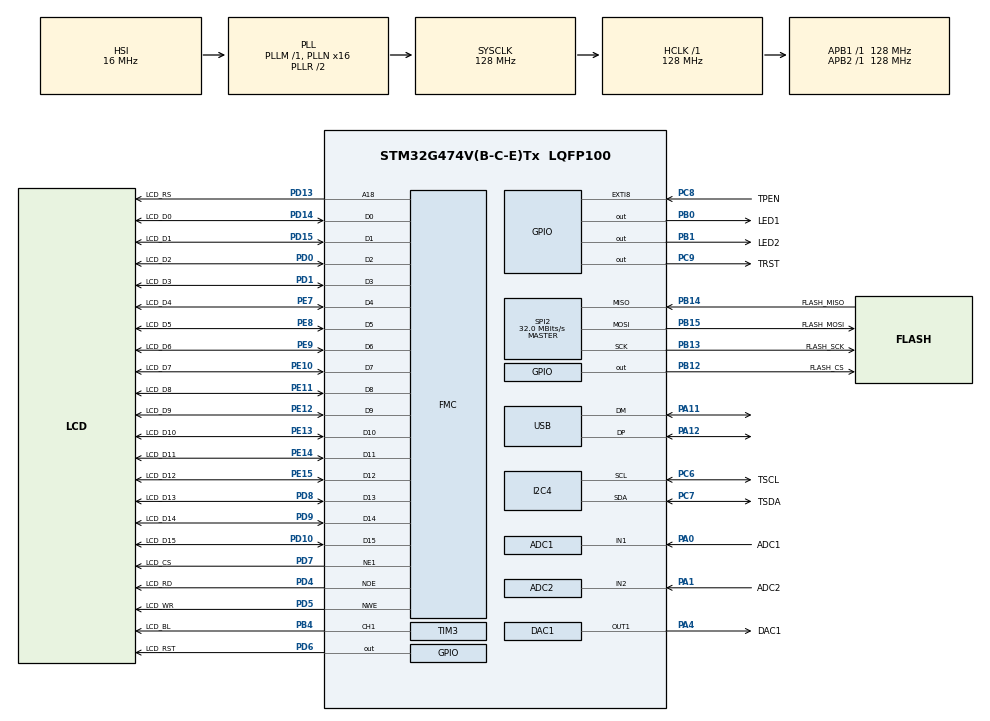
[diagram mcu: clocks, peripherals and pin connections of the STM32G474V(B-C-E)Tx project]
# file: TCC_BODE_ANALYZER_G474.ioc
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ADC1.Channel-1\#ChannelRegularConversion=ADC_CHANNEL_1
ADC1.ContinuousConvMode=DISABLE
ADC1.DMAContinuousRequests=ENABLE
ADC1.ExternalTrigConv=ADC_EXTERNALTRIG_T2_TRGO
ADC1.Mode=ADC_MODE_INDEPENDENT
ADC1.NbrOfConversionFlag=1
ADC1.OffsetNumber-1\#ChannelRegularConversion=ADC_OFFSET_NONE
ADC1.Overrun=ADC_OVR_DATA_OVERWRITTEN
ADC1.Rank-1\#ChannelRegularConversion=1
ADC1.SamplingTime-1\#ChannelRegularConversion=ADC_SAMPLETIME_2CYCLES_5
ADC1.master=1
ADC2.Channel-0\#ChannelRegularConversion=ADC_CHANNEL_2
ADC2.DMAContinuousRequests=ENABLE
ADC2.ExternalTrigConv=ADC_EXTERNALTRIG_T2_TRGO
ADC2.NbrOfConversionFlag=1
ADC2.OffsetNumber-0\#ChannelRegularConversion=ADC_OFFSET_NONE
ADC2.Rank-0\#ChannelRegularConversion=1
ADC2.SamplingTime-0\#ChannelRegularConversion=ADC_SAMPLETIME_2CYCLES_5
DAC1.DAC_OutputBuffer-DAC_OUT1=DAC_OUTPUTBUFFER_DISABLE
DAC1.DAC_Trigger_OUT1-DAC_OUT1=DAC_TRIGGER_T2_TRGO
Dma.ADC1.4.Direction=DMA_PERIPH_TO_MEMORY
Dma.ADC1.4.EventEnable=DISABLE
Dma.ADC1.4.Instance=DMA1_Channel5
Dma.ADC1.4.MemDataAlignment=DMA_MDATAALIGN_HALFWORD
Dma.ADC1.4.MemInc=DMA_MINC_ENABLE
Dma.ADC1.4.Mode=DMA_CIRCULAR
Dma.ADC1.4.PeriphDataAlignment=DMA_PDATAALIGN_HALFWORD
Dma.ADC1.4.PeriphInc=DMA_PINC_DISABLE
Dma.ADC1.4.Polarity=HAL_DMAMUX_REQ_GEN_RISING
Dma.ADC1.4.Priority=DMA_PRIORITY_HIGH
Dma.ADC1.4.RequestNumber=1
Dma.ADC1.4.SignalID=NONE
Dma.ADC1.4.SyncEnable=DISABLE
Dma.ADC1.4.SyncPolarity=HAL_DMAMUX_SYNC_NO_EVENT
Dma.ADC1.4.SyncRequestNumber=1
Dma.ADC1.4.SyncSignalID=NONE
Dma.ADC2.5.Direction=DMA_PERIPH_TO_MEMORY
Dma.ADC2.5.EventEnable=DISABLE
Dma.ADC2.5.Instance=DMA1_Channel6
Dma.ADC2.5.MemDataAlignment=DMA_MDATAALIGN_HALFWORD
Dma.ADC2.5.MemInc=DMA_MINC_ENABLE
Dma.ADC2.5.Mode=DMA_CIRCULAR
Dma.ADC2.5.PeriphDataAlignment=DMA_PDATAALIGN_HALFWORD
Dma.ADC2.5.PeriphInc=DMA_PINC_DISABLE
Dma.ADC2.5.Polarity=HAL_DMAMUX_REQ_GEN_RISING
Dma.ADC2.5.Priority=DMA_PRIORITY_HIGH
Dma.ADC2.5.RequestNumber=1
Dma.ADC2.5.SignalID=NONE
Dma.ADC2.5.SyncEnable=DISABLE
Dma.ADC2.5.SyncPolarity=HAL_DMAMUX_SYNC_NO_EVENT
Dma.ADC2.5.SyncRequestNumber=1
Dma.ADC2.5.SyncSignalID=NONE
Dma.DAC1_CH1.3.Direction=DMA_MEMORY_TO_PERIPH
Dma.DAC1_CH1.3.EventEnable=DISABLE
Dma.DAC1_CH1.3.Instance=DMA1_Channel4
Dma.DAC1_CH1.3.MemDataAlignment=DMA_MDATAALIGN_HALFWORD
Dma.DAC1_CH1.3.MemInc=DMA_MINC_ENABLE
Dma.DAC1_CH1.3.Mode=DMA_CIRCULAR
Dma.DAC1_CH1.3.PeriphDataAlignment=DMA_PDATAALIGN_WORD
Dma.DAC1_CH1.3.PeriphInc=DMA_PINC_DISABLE
Dma.DAC1_CH1.3.Polarity=HAL_DMAMUX_REQ_GEN_RISING
Dma.DAC1_CH1.3.Priority=DMA_PRIORITY_VERY_HIGH
Dma.DAC1_CH1.3.RequestNumber=1
Dma.DAC1_CH1.3.SignalID=NONE
Dma.DAC1_CH1.3.SyncEnable=DISABLE
Dma.DAC1_CH1.3.SyncPolarity=HAL_DMAMUX_SYNC_NO_EVENT
Dma.DAC1_CH1.3.SyncRequestNumber=1
Dma.DAC1_CH1.3.SyncSignalID=NONE
Dma.MEMTOMEM.2.Direction=DMA_MEMORY_TO_MEMORY
Dma.MEMTOMEM.2.EventEnable=DISABLE
Dma.MEMTOMEM.2.Instance=DMA1_Channel3
Dma.MEMTOMEM.2.MemDataAlignment=DMA_MDATAALIGN_HALFWORD
Dma.MEMTOMEM.2.MemInc=DMA_MINC_ENABLE
Dma.MEMTOMEM.2.Mode=DMA_NORMAL
Dma.MEMTOMEM.2.PeriphDataAlignment=DMA_PDATAALIGN_HALFWORD
Dma.MEMTOMEM.2.PeriphInc=DMA_PINC_ENABLE
Dma.MEMTOMEM.2.Polarity=HAL_DMAMUX_REQ_GEN_RISING
Dma.MEMTOMEM.2.Priority=DMA_PRIORITY_LOW
Dma.MEMTOMEM.2.RequestNumber=1
Dma.MEMTOMEM.2.SignalID=NONE
Dma.MEMTOMEM.2.SyncEnable=DISABLE
Dma.MEMTOMEM.2.SyncPolarity=HAL_DMAMUX_SYNC_NO_EVENT
Dma.MEMTOMEM.2.SyncRequestNumber=1
Dma.MEMTOMEM.2.SyncSignalID=NONE
Dma.Request0=SPI2_RX
Dma.Request1=SPI2_TX
Dma.Request2=MEMTOMEM
Dma.Request3=DAC1_CH1
Dma.Request4=ADC1
Dma.Request5=ADC2
Dma.SPI2_RX.0.Direction=DMA_PERIPH_TO_MEMORY
Dma.SPI2_RX.0.EventEnable=DISABLE
Dma.SPI2_RX.0.Instance=DMA1_Channel1
Dma.SPI2_RX.0.MemDataAlignment=DMA_MDATAALIGN_BYTE
Dma.SPI2_RX.0.MemInc=DMA_MINC_ENABLE
Dma.SPI2_RX.0.Mode=DMA_NORMAL
Dma.SPI2_RX.0.PeriphDataAlignment=DMA_PDATAALIGN_BYTE
Dma.SPI2_RX.0.PeriphInc=DMA_PINC_DISABLE
Dma.SPI2_RX.0.Polarity=HAL_DMAMUX_REQ_GEN_RISING
Dma.SPI2_RX.0.Priority=DMA_PRIORITY_LOW
Dma.SPI2_RX.0.RequestNumber=1
Dma.SPI2_RX.0.SignalID=NONE
Dma.SPI2_RX.0.SyncEnable=DISABLE
Dma.SPI2_RX.0.SyncPolarity=HAL_DMAMUX_SYNC_NO_EVENT
Dma.SPI2_RX.0.SyncRequestNumber=1
Dma.SPI2_RX.0.SyncSignalID=NONE
Dma.SPI2_TX.1.Direction=DMA_MEMORY_TO_PERIPH
Dma.SPI2_TX.1.EventEnable=DISABLE
Dma.SPI2_TX.1.Instance=DMA1_Channel2
Dma.SPI2_TX.1.MemDataAlignment=DMA_MDATAALIGN_BYTE
Dma.SPI2_TX.1.MemInc=DMA_MINC_ENABLE
Dma.SPI2_TX.1.Mode=DMA_NORMAL
Dma.SPI2_TX.1.PeriphDataAlignment=DMA_PDATAALIGN_BYTE
Dma.SPI2_TX.1.PeriphInc=DMA_PINC_DISABLE
Dma.SPI2_TX.1.Polarity=HAL_DMAMUX_REQ_GEN_RISING
Dma.SPI2_TX.1.Priority=DMA_PRIORITY_LOW
Dma.SPI2_TX.1.RequestNumber=1
Dma.SPI2_TX.1.SignalID=NONE
Dma.SPI2_TX.1.SyncEnable=DISABLE
Dma.SPI2_TX.1.SyncPolarity=HAL_DMAMUX_SYNC_NO_EVENT
Dma.SPI2_TX.1.SyncRequestNumber=1
Dma.SPI2_TX.1.SyncSignalID=NONE
FMC.AddressSetupTime1=0
FMC.DataSetupTime1=1
FMC.ExtendedAddressSetupTime1=0
FMC.ExtendedDataSetupTime1=1
FMC.ExtendedMode1=FMC_EXTENDED_MODE_ENABLE
FREERTOS.BinarySemaphores01=FlashDMASem,Dynamic,NULL;AcquisitionSem,Dynamic,NULL;DacIntSem,Dynamic,NULL
FREERTOS.Mutexes01=ExtFlashMtx,Dynamic,NULL
FREERTOS.Tasks01=AcquisitionTask,32,4096,AcquisitionTaskEntry,As weak,NULL,Dynamic,NULL,NULL;TouchGFXTask,8,4096,TouchGFX_Task,As external,NULL,Dynamic,NULL,NULL;SampleTouch,8,256,SampleTouch_Task,As external,NULL,Dynamic,NULL,NULL
FREERTOS.configTOTAL_HEAP_SIZE=51200
FREERTOS.configUSE_NEWLIB_REENTRANT=1
FREERTOS.configUSE_PREEMPTION=0
I2C4.I2C_Fall_Time=30
I2C4.I2C_Rise_Time=25
I2C4.Timing=0x30807DBB
Mcu.Family=STM32G4
Mcu.Name=STM32G474V(B-C-E)Tx
Mcu.Package=LQFP100
NVIC.DMA1_Channel1_IRQn=true\:5\:0\:false\:false\:true\:true\:false\:true\:true
NVIC.DMA1_Channel2_IRQn=true\:5\:0\:false\:false\:true\:true\:false\:true\:true
NVIC.DMA1_Channel3_IRQn=true\:5\:0\:false\:false\:true\:true\:true\:true\:true
NVIC.DMA1_Channel4_IRQn=true\:5\:0\:false\:false\:true\:true\:false\:true\:true
NVIC.DMA1_Channel5_IRQn=true\:5\:0\:false\:false\:true\:true\:false\:true\:true
NVIC.DMA1_Channel6_IRQn=true\:5\:0\:false\:false\:true\:true\:false\:true\:true
NVIC.PriorityGroup=NVIC_PRIORITYGROUP_4
NVIC.TIM6_DAC_IRQn=true\:15\:0\:true\:false\:true\:false\:false\:true\:true
NVIC.TIM7_DAC_IRQn=true\:5\:0\:false\:false\:true\:true\:true\:true\:true
NVIC.TimeBase=TIM6_DAC_IRQn
NVIC.TimeBaseIP=TIM6
NVIC.USB_LP_IRQn=true\:5\:0\:true\:false\:true\:true\:true\:true\:true
PA0.GPIO_Label=ADC1
PA0.Mode=IN1-Single-Ended
PA0.Signal=ADC1_IN1
PA1.GPIO_Label=ADC2
PA1.Mode=IN2-Single-Ended
PA1.Signal=ADC2_IN2
PA11.Mode=Device
PA11.Signal=USB_DM
PA12.Mode=Device
PA12.Signal=USB_DP
PA13.Mode=Serial_Wire
PA13.Signal=SYS_JTMS-SWDIO
PA14.Mode=Serial_Wire
PA14.Signal=SYS_JTCK-SWCLK
PA4.GPIO_Label=DAC1
PA4.Signal=COMP_DAC11_group
PB0.GPIO_Label=LED1
PB0.Signal=GPIO_Output
PB1.GPIO_Label=LED2
PB1.Signal=GPIO_Output
PB12.GPIO_Label=FLASH_CS
PB12.GPIO_Speed=GPIO_SPEED_FREQ_VERY_HIGH
PB12.PinState=GPIO_PIN_SET
PB12.Signal=GPIO_Output
PB13.GPIO_Label=FLASH_SCK
PB13.GPIO_Speed=GPIO_SPEED_FREQ_VERY_HIGH
PB13.Mode=Full_Duplex_Master
PB13.Signal=SPI2_SCK
PB14.GPIO_Label=FLASH_MISO
PB14.GPIO_Speed=GPIO_SPEED_FREQ_VERY_HIGH
PB14.Mode=Full_Duplex_Master
PB14.Signal=SPI2_MISO
PB15.GPIO_Label=FLASH_MOSI
PB15.GPIO_Speed=GPIO_SPEED_FREQ_VERY_HIGH
PB15.Mode=Full_Duplex_Master
PB15.Signal=SPI2_MOSI
PB4.GPIO_Label=LCD_BL
PB4.Signal=S_TIM3_CH1
PC6.GPIO_Label=TSCL
PC6.GPIO_Pu=GPIO_PULLUP
PC6.GPIO_Speed=GPIO_SPEED_FREQ_VERY_HIGH
PC6.Mode=I2C
PC6.Signal=I2C4_SCL
PC7.GPIO_Label=TSDA
PC7.GPIO_Pu=GPIO_PULLUP
PC7.GPIO_Speed=GPIO_SPEED_FREQ_VERY_HIGH
PC7.Mode=I2C
PC7.Signal=I2C4_SDA
PC8.GPIO_Label=TPEN
PC8.Signal=GPXTI8
PC9.GPIO_Label=TRST
PC9.GPIO_PuPd=GPIO_PULLUP
PC9.GPIO_Speed=GPIO_SPEED_FREQ_VERY_HIGH
PC9.PinState=GPIO_PIN_SET
PC9.Signal=GPIO_Output
PD0.GPIO_Label=LCD_D2
PD0.Mode=16b-d1
PD0.Signal=FMC_D2
PD1.GPIO_Label=LCD_D3
PD1.Mode=16b-d1
PD1.Signal=FMC_D3
PD10.GPIO_Label=LCD_D15
PD10.Mode=16b-d1
PD10.Signal=FMC_D15
PD13.GPIO_Label=LCD_RS
PD13.Mode=A18_1
PD13.Signal=FMC_A18
PD14.GPIO_Label=LCD_D0
PD14.Mode=16b-d1
PD14.Signal=FMC_D0
PD15.GPIO_Label=LCD_D1
PD15.Mode=16b-d1
PD15.Signal=FMC_D1
PD4.GPIO_Label=LCD_RD
PD4.Mode=Lcd1
PD4.Signal=FMC_NOE
PD5.GPIO_Label=LCD_WR
PD5.Mode=Lcd1
PD5.Signal=FMC_NWE
PD6.GPIO_Label=LCD_RST
PD6.GPIO_Speed=GPIO_SPEED_FREQ_VERY_HIGH
PD6.Signal=GPIO_Output
PD7.GPIO_Label=LCD_CS
PD7.Mode=NorPsramChipSelect1_1
PD7.Signal=FMC_NE1
PD8.GPIO_Label=LCD_D13
PD8.Mode=16b-d1
PD8.Signal=FMC_D13
PD9.GPIO_Label=LCD_D14
PD9.Mode=16b-d1
PD9.Signal=FMC_D14
PE10.GPIO_Label=LCD_D7
PE10.Mode=16b-d1
PE10.Signal=FMC_D7
PE11.GPIO_Label=LCD_D8
PE11.Mode=16b-d1
PE11.Signal=FMC_D8
PE12.GPIO_Label=LCD_D9
PE12.Mode=16b-d1
PE12.Signal=FMC_D9
PE13.GPIO_Label=LCD_D10
PE13.Mode=16b-d1
PE13.Signal=FMC_D10
PE14.GPIO_Label=LCD_D11
PE14.Mode=16b-d1
PE14.Signal=FMC_D11
PE15.GPIO_Label=LCD_D12
PE15.Mode=16b-d1
PE15.Signal=FMC_D12
PE7.GPIO_Label=LCD_D4
PE7.Mode=16b-d1
PE7.Signal=FMC_D4
PE8.GPIO_Label=LCD_D5
PE8.Mode=16b-d1
PE8.Signal=FMC_D5
PE9.GPIO_Label=LCD_D6
PE9.Mode=16b-d1
PE9.Signal=FMC_D6
ProjectManager.HeapSize=0x2000
ProjectManager.StackSize=0x1000
ProjectManager.TargetToolchain=STM32CubeIDE
RCC.ADC12CLockSelection=RCC_ADC12CLKSOURCE_PLL
RCC.ADC12Freq_Value=128000000
RCC.ADC345Freq_Value=128000000
RCC.AHBFreq_Value=128000000
RCC.APB1Freq_Value=128000000
RCC.APB1TimFreq_Value=128000000
RCC.APB2Freq_Value=128000000
RCC.APB2TimFreq_Value=128000000
RCC.CK48CLockSelection=RCC_USBCLKSOURCE_HSI48
RCC.CortexFreq_Value=128000000
RCC.EXTERNAL_CLOCK_VALUE=12288000
RCC.HCLKFreq_Value=128000000
RCC.HSE_VALUE=8000000
RCC.HSI48_VALUE=48000000
RCC.HSI_VALUE=16000000
RCC.LSE_VALUE=32768
RCC.PLLN=16
RCC.SYSCLKFreq_VALUE=128000000
RCC.SYSCLKSource=RCC_SYSCLKSOURCE_PLLCLK
RCC.USBFreq_Value=48000000
RCC.VCOOutputFreq_Value=256000000
SH.COMP_DAC11_group.0=DAC1_OUT1,DAC_OUT1
SH.S_TIM3_CH1.0=TIM3_CH1,PWM Generation1 CH1
SPI2.BaudRatePrescaler=SPI_BAUDRATEPRESCALER_4
SPI2.CalculateBaudRate=32.0 MBits/s
SPI2.DataSize=SPI_DATASIZE_8BIT
SPI2.Direction=SPI_DIRECTION_2LINES
SPI2.Mode=SPI_MODE_MASTER
SPI2.VirtualType=VM_MASTER
STMicroelectronics.X-CUBE-TOUCHGFX.4.22.1.ApplicationCcGraphicsJjApplication=TouchGFXOoGenerator
STMicroelectronics.X-CUBE-TOUCHGFX.4.22.1.tgfx_block_size=4800
STMicroelectronics.X-CUBE-TOUCHGFX.4.22.1.tgfx_buffering_strategy=Partial
STMicroelectronics.X-CUBE-TOUCHGFX.4.22.1.tgfx_custom_height=800
STMicroelectronics.X-CUBE-TOUCHGFX.4.22.1.tgfx_custom_width=480
STMicroelectronics.X-CUBE-TOUCHGFX.4.22.1.tgfx_datareader=Enabled
STMicroelectronics.X-CUBE-TOUCHGFX.4.22.1.tgfx_datareader_block_size=1875
STMicroelectronics.X-CUBE-TOUCHGFX.4.22.1.tgfx_datareader_dma_transfersize=2048
STMicroelectronics.X-CUBE-TOUCHGFX.4.22.1.tgfx_datareader_mem_base_address=0x00000000
STMicroelectronics.X-CUBE-TOUCHGFX.4.22.1.tgfx_datareader_mem_size=16777216
STMicroelectronics.X-CUBE-TOUCHGFX.4.22.1.tgfx_display_interface=disp_fmc
STMicroelectronics.X-CUBE-TOUCHGFX.4.22.1_IsPackSelfContextualization=true
TIM2.PeriodNoDither=3
TIM2.Prescaler=31
TIM2.TIM_MasterOutputTrigger=TIM_TRGO_UPDATE
TIM3.AutoReloadPreload=TIM_AUTORELOAD_PRELOAD_ENABLE
TIM3.Channel-PWM\ Generation1\ CH1=TIM_CHANNEL_1
TIM3.PeriodNoDither=999
TIM3.Prescaler=3
TIM7.PeriodNoDither=110
TIM7.Prescaler=19199
USB_DEVICE.CLASS_NAME_FS=MSC
USB_DEVICE.VirtualMode=Msc
USB_DEVICE.VirtualModeFS=Msc_FS
VP_CRC_VS_CRC.Mode=CRC_Activate
VP_FREERTOS_VS_CMSIS_V2.Mode=CMSIS_V2
VP_STMicroelectronics.X-CUBE-TOUCHGFX_VS_GraphicsJjApplication_4.22.1.Mode=GraphicsJjApplication
VP_SYS_VS_tim6.Mode=TIM6
VP_TIM2_VS_ClockSourceINT.Mode=Internal
VP_TIM7_VS_ClockSourceINT.Mode=Enable_Timer
VP_USB_DEVICE_VS_USB_DEVICE_MSC_FS.Mode=MSC_FS
board=custom

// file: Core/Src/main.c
/* USER CODE BEGIN Header */
/**
 ******************************************************************************
 * @file           : main.c
 * @brief          : Main program body
 ******************************************************************************
 * @attention
 *
 * Copyright (c) 2023 STMicroelectronics.
 * All rights reserved.
 *
 * This software is licensed under terms that can be found in the LICENSE file
 * in the root directory of this software component.
 * If no LICENSE file comes with this software, it is provided AS-IS.
 *
 ******************************************************************************
 */
/* USER CODE END Header */
#include "main.h"
#include "cmsis_os.h"
#include "adc.h"
#include "crc.h"
#include "dac.h"
#include "dma.h"
#include "i2c.h"
#include "spi.h"
#include "tim.h"
#include "gpio.h"
#include "fmc.h"
#include "app_touchgfx.h"

/* USER CODE BEGIN Includes */
#include "app_filesystem.h"
#include "usb_device.h"
/* USER CODE END Includes */

void SystemClock_Config(void);
void MX_FREERTOS_Init(void);

int main(void)
{

  /* MCU Configuration--------------------------------------------------------*/

  /* Reset of all peripherals, Initializes the Flash interface and the Systick. */
  HAL_Init();

  /* Configure the system clock */
  SystemClock_Config();

  /* Initialize all configured peripherals */
  MX_GPIO_Init();
  MX_DMA_Init();
  MX_I2C4_Init();
  MX_SPI2_Init();
  MX_TIM3_Init();
  MX_TIM7_Init();
  MX_FMC_Init();
  MX_CRC_Init();
  MX_DAC1_Init();
  MX_TIM2_Init();
  MX_ADC1_Init();
  MX_ADC2_Init();
  MX_TouchGFX_Init();
  /* Call PreOsInit function */
  MX_TouchGFX_PreOSInit();
  /* USER CODE BEGIN 2 */
	/* Initialize the File System */
	APP_FileSystemInit();
	/* Initialize the USB */
	MX_USB_Device_Init();
  /* USER CODE END 2 */

  /* Init scheduler */
  osKernelInitialize();  /* Call init function for freertos objects (in freertos.c) */
  MX_FREERTOS_Init();

  /* Start scheduler */
  osKernelStart();
  /* We should never get here as control is now taken by the scheduler */
  /* Infinite loop */
	while (1)
	{

	}
}

void SystemClock_Config(void)
{
  RCC_OscInitTypeDef RCC_OscInitStruct = {0};
  RCC_ClkInitTypeDef RCC_ClkInitStruct = {0};

  /** Configure the main internal regulator output voltage
  */
  HAL_PWREx_ControlVoltageScaling(PWR_REGULATOR_VOLTAGE_SCALE1);

  /** Initializes the RCC Oscillators according to the specified parameters
  * in the RCC_OscInitTypeDef structure.
  */
  RCC_OscInitStruct.OscillatorType = RCC_OSCILLATORTYPE_HSI|RCC_OSCILLATORTYPE_HSI48;
  RCC_OscInitStruct.HSIState = RCC_HSI_ON;
  RCC_OscInitStruct.HSICalibrationValue = RCC_HSICALIBRATION_DEFAULT;
  RCC_OscInitStruct.HSI48State = RCC_HSI48_ON;
  RCC_OscInitStruct.PLL.PLLState = RCC_PLL_ON;
  RCC_OscInitStruct.PLL.PLLSource = RCC_PLLSOURCE_HSI;
  RCC_OscInitStruct.PLL.PLLM = RCC_PLLM_DIV1;
  RCC_OscInitStruct.PLL.PLLN = 16;
  RCC_OscInitStruct.PLL.PLLP = RCC_PLLP_DIV2;
  RCC_OscInitStruct.PLL.PLLQ = RCC_PLLQ_DIV2;
  RCC_OscInitStruct.PLL.PLLR = RCC_PLLR_DIV2;
  if (HAL_RCC_OscConfig(&RCC_OscInitStruct) != HAL_OK)
  {
    Error_Handler();
  }

  /** Initializes the CPU, AHB and APB buses clocks
  */
  RCC_ClkInitStruct.ClockType = RCC_CLOCKTYPE_HCLK|RCC_CLOCKTYPE_SYSCLK
                              |RCC_CLOCKTYPE_PCLK1|RCC_CLOCKTYPE_PCLK2;
  RCC_ClkInitStruct.SYSCLKSource = RCC_SYSCLKSOURCE_PLLCLK;
  RCC_ClkInitStruct.AHBCLKDivider = RCC_SYSCLK_DIV1;
  RCC_ClkInitStruct.APB1CLKDivider = RCC_HCLK_DIV1;
  RCC_ClkInitStruct.APB2CLKDivider = RCC_HCLK_DIV1;

  if (HAL_RCC_ClockConfig(&RCC_ClkInitStruct, FLASH_LATENCY_4) != HAL_OK)
  {
    Error_Handler();
  }
}

/* USER CODE BEGIN 4 */
void vApplicationStackOverflowHook (TaskHandle_t xTask, signed char *pcTaskName)
{
	HAL_GPIO_WritePin(LED1_GPIO_Port, LED1_Pin, GPIO_PIN_SET);
}
/* USER CODE END 4 */

void HAL_TIM_PeriodElapsedCallback(TIM_HandleTypeDef *htim)
{
  if (htim->Instance == TIM6) {
    HAL_IncTick();
  }
}

void Error_Handler(void)
{
	__disable_irq();
	while (1)
	{
	}
}

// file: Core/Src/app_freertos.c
/* USER CODE BEGIN Header */
/**
  ******************************************************************************
  * File Name          : app_freertos.c
  * Description        : Code for freertos applications
  ******************************************************************************
  * @attention
  *
  * Copyright (c) 2023 STMicroelectronics.
  * All rights reserved.
  *
  * This software is licensed under terms that can be found in the LICENSE file
  * in the root directory of this software component.
  * If no LICENSE file comes with this software, it is provided AS-IS.
  *
  ******************************************************************************
  */
/* USER CODE END Header */

#include "FreeRTOS.h"
#include "task.h"
#include "main.h"
#include "cmsis_os.h"

/* Definitions for AcquisitionTask */
osThreadId_t AcquisitionTaskHandle;
const osThreadAttr_t AcquisitionTask_attributes = {
  .name = "AcquisitionTask",
  .priority = (osPriority_t) osPriorityAboveNormal,
  .stack_size = 4096 * 4
};
/* Definitions for TouchGFXTask */
osThreadId_t TouchGFXTaskHandle;
const osThreadAttr_t TouchGFXTask_attributes = {
  .name = "TouchGFXTask",
  .priority = (osPriority_t) osPriorityLow,
  .stack_size = 4096 * 4
};
/* Definitions for SampleTouch */
osThreadId_t SampleTouchHandle;
const osThreadAttr_t SampleTouch_attributes = {
  .name = "SampleTouch",
  .priority = (osPriority_t) osPriorityLow,
  .stack_size = 256 * 4
};
/* Definitions for ExtFlashMtx */
osMutexId_t ExtFlashMtxHandle;
const osMutexAttr_t ExtFlashMtx_attributes = {
  .name = "ExtFlashMtx"
};
/* Definitions for FlashDMASem */
osSemaphoreId_t FlashDMASemHandle;
const osSemaphoreAttr_t FlashDMASem_attributes = {
  .name = "FlashDMASem"
};
/* Definitions for AcquisitionSem */
osSemaphoreId_t AcquisitionSemHandle;
const osSemaphoreAttr_t AcquisitionSem_attributes = {
  .name = "AcquisitionSem"
};
/* Definitions for DacIntSem */
osSemaphoreId_t DacIntSemHandle;
const osSemaphoreAttr_t DacIntSem_attributes = {
  .name = "DacIntSem"
};

void AcquisitionTaskEntry(void *argument);
extern void TouchGFX_Task(void *argument);
extern void SampleTouch_Task(void *argument);

void MX_FREERTOS_Init(void); /* (MISRA C 2004 rule 8.1) */

void MX_FREERTOS_Init(void) {
  /* Create the mutex(es) */
  /* creation of ExtFlashMtx */
  ExtFlashMtxHandle = osMutexNew(&ExtFlashMtx_attributes);

  /* Create the semaphores(s) */
  /* creation of FlashDMASem */
  FlashDMASemHandle = osSemaphoreNew(1, 1, &FlashDMASem_attributes);

  /* creation of AcquisitionSem */
  AcquisitionSemHandle = osSemaphoreNew(1, 1, &AcquisitionSem_attributes);

  /* creation of DacIntSem */
  DacIntSemHandle = osSemaphoreNew(1, 1, &DacIntSem_attributes);

  /* USER CODE BEGIN RTOS_SEMAPHORES */
  /* add semaphores, ... */
  osSemaphoreAcquire(FlashDMASemHandle, osWaitForever);
  osSemaphoreAcquire(AcquisitionSemHandle, osWaitForever);
  osSemaphoreAcquire(DacIntSemHandle, osWaitForever);
  /* USER CODE END RTOS_SEMAPHORES */

  /* Create the thread(s) */
  /* creation of AcquisitionTask */
  AcquisitionTaskHandle = osThreadNew(AcquisitionTaskEntry, NULL, &AcquisitionTask_attributes);

  /* creation of TouchGFXTask */
  TouchGFXTaskHandle = osThreadNew(TouchGFX_Task, NULL, &TouchGFXTask_attributes);

  /* creation of SampleTouch */
  SampleTouchHandle = osThreadNew(SampleTouch_Task, NULL, &SampleTouch_attributes);

}

__weak void AcquisitionTaskEntry(void *argument)
{
  for(;;)
  {
    osDelay(1);
  }
}
